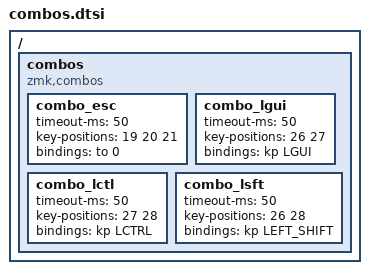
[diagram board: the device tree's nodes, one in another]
/ {
    combos {
        compatible = "zmk,combos";
        combo_esc {
            timeout-ms = <50>;
            key-positions = <19 20 21>;
            bindings = <&to 0>;
        };

        combo_lgui {
            timeout-ms = <50>;
            key-positions = <26 27>;
            bindings = <&kp LGUI>;
        };

        combo_lctl {
            timeout-ms = <50>;
            key-positions = <27 28>;
            bindings = <&kp LCTRL>;
        };

        combo_lsft {
            timeout-ms = <50>;
            key-positions = <26 28>;
            bindings = <&kp LEFT_SHIFT>;
        };
    };
};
